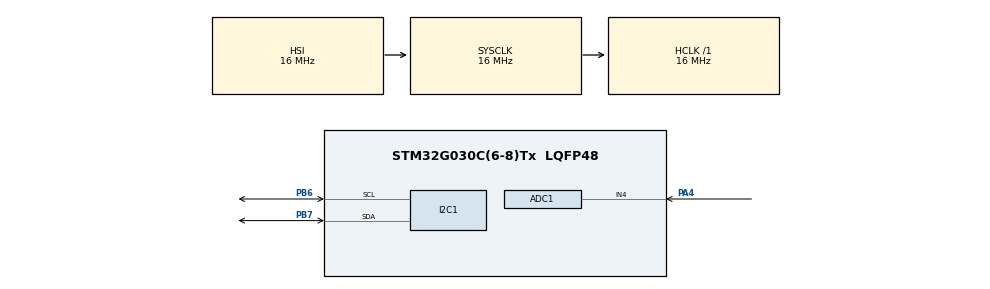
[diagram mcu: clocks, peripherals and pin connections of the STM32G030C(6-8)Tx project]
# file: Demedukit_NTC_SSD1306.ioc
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ADC1.Channel-0\#ChannelRegularConversion=ADC_CHANNEL_4
ADC1.ContinuousConvMode=ENABLE
ADC1.NbrOfConversionFlag=1
ADC1.Rank-0\#ChannelRegularConversion=1
ADC1.SamplingTime-0\#ChannelRegularConversion=ADC_SAMPLINGTIME_COMMON_1
ADC1.SelectedChannel=ADC_CHANNEL_4
ADC1.master=1
I2C1.Timing=0x00503D58
Mcu.Family=STM32G0
Mcu.Name=STM32G030C(6-8)Tx
Mcu.Package=LQFP48
PA13.Mode=Serial_Wire
PA13.Signal=SYS_SWDIO
PA14-BOOT0.Mode=Serial_Wire
PA14-BOOT0.Signal=SYS_SWCLK
PA4.Mode=IN4
PA4.Signal=ADC1_IN4
PB6.Mode=I2C
PB6.Signal=I2C1_SCL
PB7.Mode=I2C
PB7.Signal=I2C1_SDA
PC14-OSC32_IN\ (PC14).Mode=LSE-External-Oscillator
PC14-OSC32_IN\ (PC14).Signal=RCC_OSC32_IN
PC15-OSC32_OUT\ (PC15).Mode=LSE-External-Oscillator
PC15-OSC32_OUT\ (PC15).Signal=RCC_OSC32_OUT
PF0-OSC_IN\ (PF0).Mode=HSE-External-Oscillator
PF0-OSC_IN\ (PF0).Signal=RCC_OSC_IN
PF1-OSC_OUT\ (PF1).Mode=HSE-External-Oscillator
PF1-OSC_OUT\ (PF1).Signal=RCC_OSC_OUT
ProjectManager.HeapSize=0x200
ProjectManager.StackSize=0x400
ProjectManager.TargetToolchain=STM32CubeIDE
RCC.AHBFreq_Value=16000000
RCC.CortexFreq_Value=16000000
RCC.EXTERNAL_CLOCK_VALUE=12288000
RCC.HCLKFreq_Value=16000000
RCC.HSE_VALUE=8000000
RCC.HSI_VALUE=16000000
RCC.SYSCLKFreq_VALUE=16000000
RCC.VCOOutputFreq_Value=128000000
board=custom

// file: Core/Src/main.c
/* USER CODE BEGIN Header */
/**
  ******************************************************************************
  * @file           : main.c
  * @brief          : Main program body
  ******************************************************************************
  * @attention
  *
  * Copyright (c) 2024 STMicroelectronics.
  * All rights reserved.
  *
  * This software is licensed under terms that can be found in the LICENSE file
  * in the root directory of this software component.
  * If no LICENSE file comes with this software, it is provided AS-IS.
  *
  ******************************************************************************
  */
/* USER CODE END Header */
#include "main.h"

/* USER CODE BEGIN Includes */
#include "ssd1306.h"
#include "stdio.h"
#include "string.h"
#include "math.h"
/* USER CODE END Includes */

ADC_HandleTypeDef hadc1;

I2C_HandleTypeDef hi2c1;

void SystemClock_Config(void);
static void MX_GPIO_Init(void);
static void MX_ADC1_Init(void);
static void MX_I2C1_Init(void);

/* USER CODE BEGIN 0 */
double termistor(uint32_t analogValue)
{
	double temperature;
	uint32_t adcval = 4096-analogValue;
	temperature = log((adcval*10000)/(4095-adcval));
	temperature = 1 / (0.001129148 + (0.000234125 + (0.0000000876741 * temperature * temperature)) * temperature);
	temperature = temperature - 273.15;
	return temperature;

}

double temp1;
char buffer[10];
volatile uint32_t adcValues[10];
/* USER CODE END 0 */

int main(void)
{

  /* MCU Configuration--------------------------------------------------------*/

  /* Reset of all peripherals, Initializes the Flash interface and the Systick. */
  HAL_Init();

  /* Configure the system clock */
  SystemClock_Config();

  /* Initialize all configured peripherals */
  MX_GPIO_Init();
  MX_ADC1_Init();
  MX_I2C1_Init();
  /* USER CODE BEGIN 2 */
  HAL_ADC_Start(&hadc1);
  ssd1306_Init();
  ssd1306_Fill(Black);
  /* USER CODE END 2 */

  /* Infinite loop */
  /* USER CODE BEGIN WHILE */
  while (1)
  {
	  HAL_ADC_PollForConversion(&hadc1, 50);
	  adcValues[2] = HAL_ADC_GetValue(&hadc1);
	  temp1 = (termistor(adcValues[2]) - 10);
	  snprintf(buffer, 10, "%f", temp1);
	  ssd1306_SetCursor(15, 2);
	  ssd1306_WriteString("SICAKLIK", Font_11x18, White);
	  ssd1306_SetCursor(14, 27);
	  ssd1306_WriteString(buffer, Font_11x18, White);
	  ssd1306_SetCursor(45, 46);
	  ssd1306_UpdateScreen();
	  HAL_Delay(50);
    /* USER CODE END WHILE */

  }
}

void SystemClock_Config(void)
{
  RCC_OscInitTypeDef RCC_OscInitStruct = {0};
  RCC_ClkInitTypeDef RCC_ClkInitStruct = {0};

  /** Configure the main internal regulator output voltage
  */
  HAL_PWREx_ControlVoltageScaling(PWR_REGULATOR_VOLTAGE_SCALE1);

  /** Initializes the RCC Oscillators according to the specified parameters
  * in the RCC_OscInitTypeDef structure.
  */
  RCC_OscInitStruct.OscillatorType = RCC_OSCILLATORTYPE_HSI;
  RCC_OscInitStruct.HSIState = RCC_HSI_ON;
  RCC_OscInitStruct.HSIDiv = RCC_HSI_DIV1;
  RCC_OscInitStruct.HSICalibrationValue = RCC_HSICALIBRATION_DEFAULT;
  RCC_OscInitStruct.PLL.PLLState = RCC_PLL_NONE;
  if (HAL_RCC_OscConfig(&RCC_OscInitStruct) != HAL_OK)
  {
    Error_Handler();
  }

  /** Initializes the CPU, AHB and APB buses clocks
  */
  RCC_ClkInitStruct.ClockType = RCC_CLOCKTYPE_HCLK|RCC_CLOCKTYPE_SYSCLK
                              |RCC_CLOCKTYPE_PCLK1;
  RCC_ClkInitStruct.SYSCLKSource = RCC_SYSCLKSOURCE_HSI;
  RCC_ClkInitStruct.AHBCLKDivider = RCC_SYSCLK_DIV1;
  RCC_ClkInitStruct.APB1CLKDivider = RCC_HCLK_DIV1;

  if (HAL_RCC_ClockConfig(&RCC_ClkInitStruct, FLASH_LATENCY_0) != HAL_OK)
  {
    Error_Handler();
  }
}

static void MX_ADC1_Init(void)
{

  ADC_ChannelConfTypeDef sConfig = {0};

  /** Configure the global features of the ADC (Clock, Resolution, Data Alignment and number of conversion)
  */
  hadc1.Instance = ADC1;
  hadc1.Init.ClockPrescaler = ADC_CLOCK_SYNC_PCLK_DIV2;
  hadc1.Init.Resolution = ADC_RESOLUTION_12B;
  hadc1.Init.DataAlign = ADC_DATAALIGN_RIGHT;
  hadc1.Init.ScanConvMode = ADC_SCAN_DISABLE;
  hadc1.Init.EOCSelection = ADC_EOC_SINGLE_CONV;
  hadc1.Init.LowPowerAutoWait = DISABLE;
  hadc1.Init.LowPowerAutoPowerOff = DISABLE;
  hadc1.Init.ContinuousConvMode = ENABLE;
  hadc1.Init.NbrOfConversion = 1;
  hadc1.Init.ExternalTrigConv = ADC_SOFTWARE_START;
  hadc1.Init.ExternalTrigConvEdge = ADC_EXTERNALTRIGCONVEDGE_NONE;
  hadc1.Init.DMAContinuousRequests = DISABLE;
  hadc1.Init.Overrun = ADC_OVR_DATA_PRESERVED;
  hadc1.Init.SamplingTimeCommon1 = ADC_SAMPLETIME_1CYCLE_5;
  hadc1.Init.SamplingTimeCommon2 = ADC_SAMPLETIME_1CYCLE_5;
  hadc1.Init.OversamplingMode = DISABLE;
  hadc1.Init.TriggerFrequencyMode = ADC_TRIGGER_FREQ_HIGH;
  if (HAL_ADC_Init(&hadc1) != HAL_OK)
  {
    Error_Handler();
  }

  /** Configure Regular Channel
  */
  sConfig.Channel = ADC_CHANNEL_4;
  sConfig.Rank = ADC_REGULAR_RANK_1;
  sConfig.SamplingTime = ADC_SAMPLINGTIME_COMMON_1;
  if (HAL_ADC_ConfigChannel(&hadc1, &sConfig) != HAL_OK)
  {
    Error_Handler();
  }

}

static void MX_I2C1_Init(void)
{

  hi2c1.Instance = I2C1;
  hi2c1.Init.Timing = 0x00503D58;
  hi2c1.Init.OwnAddress1 = 0;
  hi2c1.Init.AddressingMode = I2C_ADDRESSINGMODE_7BIT;
  hi2c1.Init.DualAddressMode = I2C_DUALADDRESS_DISABLE;
  hi2c1.Init.OwnAddress2 = 0;
  hi2c1.Init.OwnAddress2Masks = I2C_OA2_NOMASK;
  hi2c1.Init.GeneralCallMode = I2C_GENERALCALL_DISABLE;
  hi2c1.Init.NoStretchMode = I2C_NOSTRETCH_DISABLE;
  if (HAL_I2C_Init(&hi2c1) != HAL_OK)
  {
    Error_Handler();
  }

  /** Configure Analogue filter
  */
  if (HAL_I2CEx_ConfigAnalogFilter(&hi2c1, I2C_ANALOGFILTER_ENABLE) != HAL_OK)
  {
    Error_Handler();
  }

  /** Configure Digital filter
  */
  if (HAL_I2CEx_ConfigDigitalFilter(&hi2c1, 0) != HAL_OK)
  {
    Error_Handler();
  }

}

static void MX_GPIO_Init(void)
{

  /* GPIO Ports Clock Enable */
  __HAL_RCC_GPIOC_CLK_ENABLE();
  __HAL_RCC_GPIOF_CLK_ENABLE();
  __HAL_RCC_GPIOA_CLK_ENABLE();
  __HAL_RCC_GPIOB_CLK_ENABLE();

}

void Error_Handler(void)
{
  __disable_irq();
  while (1)
  {
  }
}
